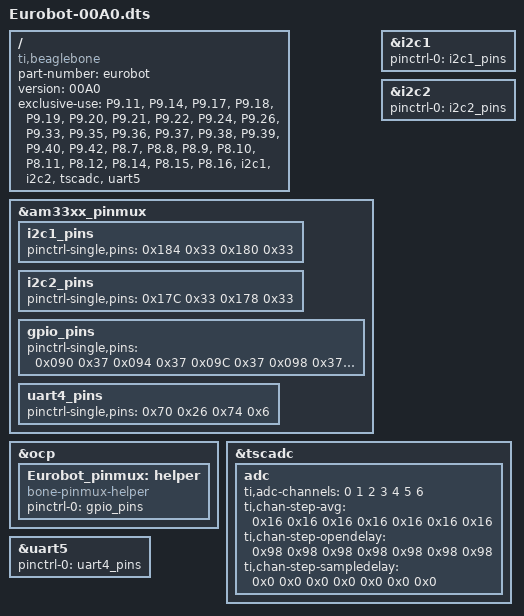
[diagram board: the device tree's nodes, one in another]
/*
 * Eurobot Tree Overlay
 * This overlay is responsible for enabling the various components used for Eurobot and the corresponding cape.
 * The following features are enabled:
 *  - SPI0-0 on pins 17 (CS) 18 (DOutput) 21 (DInput) 22 (CLK)
 *  - SPI0-1 0 and 1 on pins 28 (CS0) 29 (DInput) 30 (DOutput) 31 (CLK) 42 (CS1)
 *  - I2C-1 on pins 19 (SCL) and 20 (SDA)
 *  - I2C-2 on pins 24 (SCL) and 26 (SDA)
 *  - GPIO 67-69-68-45-44-26-47-46 as input with pullup
 *  - GPIO 46-47 as output
 *  - all 7 analog input are enabled
 *  - UART 4
 *
 * Note that the /dev/* names do not match those of the prots. For now:
 *  - I2C 1 maps to /dev/i2c-2
 *  - I2C 2 maps to /dev/i2c-1
 *  - SPI 0.0 maps to /dev/spidev1.0
 *  - SPI 1.0 maps to /dev/spidev2.0
 *  - SPI 1.1 maps to /dev/spidev2.1
 *
 * To change I2C frequency, please look at am335x-boneblack.dts.
 * To get pin offset and pin mode values, see for example:
 * http://www.embedded-things.com/bbb/beaglebone-black-pin-mux-spreadsheet/
 *
 * To compile this file run:
 * dtc -O dtb -o Eurobot-00A0.dtbo -b 00 -@ Eurobot-00A0.dts
 */
/dts-v1/;
/plugin/;


/ {
    compatible = "ti,beaglebone", "ti,beaglebone-black";

    /* identification */
    part-number = "eurobot";
	version = "00A0";

	/* Define pins with exclusive use */
	exclusive-use =
		"P9.11",
		"P9.14",
		"P9.17",
		"P9.18",
		"P9.19",
		"P9.20",
		"P9.21",
		"P9.22",
		"P9.24",
		"P9.26",
		"P9.33",
		"P9.35",
		"P9.36",
		"P9.37",
		"P9.38",
		"P9.39",
		"P9.40",
		"P9.42",
		"P8.7",
		"P8.8",
		"P8.9",
		"P8.10",
		"P8.11",
		"P8.12",
		"P8.14",
		"P8.15",
		"P8.16",
		"i2c1",
		"i2c2",
		"tscadc",
		"uart5";

	/* Define pin usage*/
    fragment@0 {
        target = <&am33xx_pinmux>;
        __overlay__ {
            i2c1_pins: i2c1_pins {
                        pinctrl-single,pins = <
                                0x184 0x33      /* P9.24 - SCL - INPUT_PULLUP | MODE3 */
                                0x180 0x33      /* P9.26 - SDA - INPUT_PULLUP | MODE3 */
                >;
            };
            i2c2_pins: i2c2_pins {
                        pinctrl-single,pins = <
                                0x17C 0x33      /* P9.19 - SCL - INPUT_PULLUP | MODE3 */
                                0x178 0x33      /* P9.20 - SDA - INPUT_PULLUP | MODE3 */
                >;
            };
			gpio_pins: gpio_pins {
				pinctrl-single,pins = <
								/* Exposed GPIO ports*/
                                0x090 0x37      /* P8.7 - GPIO66 - INPUT_PULLUP | MODE7 */
                                0x094 0x37      /* P8.8 - GPIO67 - INPUT_PULLUP | MODE7 */
                                0x09C 0x37      /* P8.9 - GPIO69 - INPUT_PULLUP | MODE7 */
                                0x098 0x37      /* P8.10 - GPIO68 - INPUT_PULLUP | MODE7 */
                                0x034 0x37      /* P8.11 - GPIO45 - INPUT_PULLUP | MODE7 */
                                0x030 0x37      /* P8.12 - GPIO44 - INPUT_PULLUP | MODE7 */
                                0x028 0x37      /* P8.14 - GPIO26 - INPUT_PULLUP | MODE7 */
								/* LED ports */
                                0x03C 0x07      /* P8.15 - GPIO47 - OUTPUT | MODE7 */
                                0x038 0x07      /* P8.16 - GPIO46 - OUTPUT | MODE7 */
                >;
            };
            uart4_pins: uart4_pins {
				pinctrl-single,pins = <
								0x70 0x26
								0x74 0x6
                >;
            };
        };
    };

    /* I2C1*/
    fragment@4 {
        target = <&i2c1>;
        __overlay__ {
             #address-cells = <1>;
             #size-cells = <0>;
             status = "okay";
             pinctrl-names = "default";
             pinctrl-0 = <&i2c1_pins>;
        };
    };

    /* I2C2*/
    fragment@5 {
        target = <&i2c2>;
        __overlay__ {
             #address-cells = <1>;
             #size-cells = <0>;
             status = "okay";
             pinctrl-names = "default";
             pinctrl-0 = <&i2c2_pins>;
        };
    };

    /* GPIO*/
    fragment@6 {
        target = <&ocp>;
        __overlay__ {
            Eurobot_pinmux: helper {
                compatible = "bone-pinmux-helper";
                pinctrl-names = "default";
                pinctrl-0 = <&gpio_pins>;
                status = "okay";
            };
        };
    };

    /* ADC */
    fragment@7 {
		target = <&tscadc>;
		__overlay__ {

			status = "okay";
			adc {
				ti,adc-channels = <0 1 2 3 4 5 6>;
				ti,chan-step-avg = <0x16 0x16 0x16 0x16 0x16 0x16 0x16>;
				ti,chan-step-opendelay = <0x98 0x98 0x98 0x98 0x98 0x98 0x98>;
				ti,chan-step-sampledelay = <0x0 0x0 0x0 0x0 0x0 0x0 0x0>;
			};
		};
	};

	/* UART */
	fragment@8 {
        target = <&uart5>;
        __overlay__ {
             status = "okay";
             pinctrl-names = "default";
             pinctrl-0 = <&uart4_pins>;
        };
    };

};
